# NUC1xx_registers register map
File version: 0.1
CPU: 
Registers are 32-bit, read-write, reset 0x0 unless marked. A register's access mark holds for its fields unless they carry their own. Offsets are from the block's base; [hi:lo] are bit positions; lines under a group give offsets from that group; {n}, {i} and the like mark numbered series.

## GPA — Registers group
Base 0x50004000
Same registers: GPB 0x50004040, GPC 0x50004080, GPD 0x500040C0, GPE 0x50004100
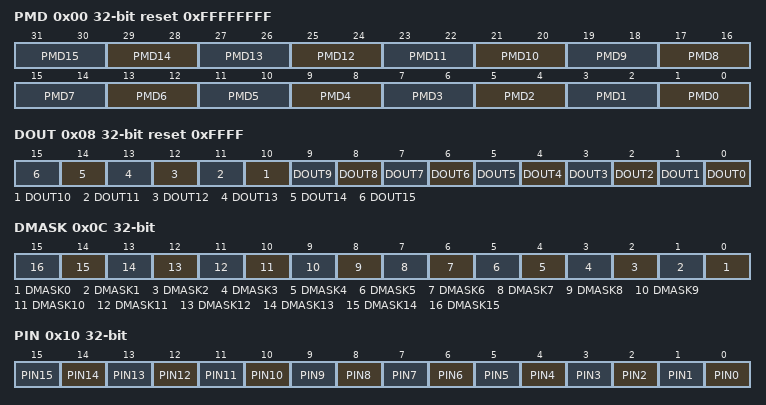
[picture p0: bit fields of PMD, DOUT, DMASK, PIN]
0x00 PMD reset 0xFFFFFFFF (reset mask 0x0) — GPIO Port Pin I/O Mode Control
  [2n+1:2n] PMD{n} (n=0..15) — GPIOX I/O Pin[n] Mode Control Determine each I/O type of GPIOx pins 00 = GPIO port [n] pin is in INPUT mode. 01 = GPIO port [n] pin is in OUTPUT mode. 10 = GPIO port [n] pin is in Open-Drain mode. 11 = GPIO port [n] pin is in Quasi-bidirectional mode.
0x04 OFFD — GPIO Port Pin OFF Digital Enable
  [31:16] OFFD — GPIOx Pin[n] OFF digital input path Enable Each of these bits is used to control if the input path of corresponding GPIO pin is disabled. If input is analog signal, users can OFF digital input path to avoid creepage 1 = Disable IO digital input path (digital input tied to low) 0 = Enable IO digital input path
0x08 DOUT reset 0xFFFF (reset mask 0xFFFF0000) — GPIO Port Data Output Value
  [n] DOUT{n} (n=0..15) — GPIOx Pin[n] Output Value Each of these bits control the status of a GPIO pin when the GPIO pin is configures as output, open-drain and quasi-mode. 1 = GPIO port [A/B/C/D/E] Pin[n] will drive High if the GPIO pin is configures as output, open-drain and quasi-mode. 0 = GPIO port [A/B/C/D/E] Pin[n] will drive Low if the GPIO pin is configures as output, open-drain and quasi-mode.
0x0C DMASK — GPIO Port Data Output Write Mask
  [n] DMASK{n} (n=0..15) — Port [A/B/C/D/E] Data Output Write Mask These bits are used to protect the corresponding register of GPIOx_DOUT bit[n]. When set the DMASK bit[n] to"1", the corresponding GPIOx_DOUTn bit is protected. The write signal is masked, write data to the protect bit is ignored 1 = The corresponding GPIOx_DOUT[n] bit is protected 0 = The corresponding GPIOx_DOUT[n] bit can be updated
0x10 PIN ro (reset mask 0xFFFF0000) — GPIO Port Pin Value
  [n] PIN{n} (n=0..15) — Port [A/B/C/D/E] Pin Values Each bit of the register reflects the actual status of the respective GPIO pin If bit is 1, it indicates the corresponding pin status is high, else the pin status is low
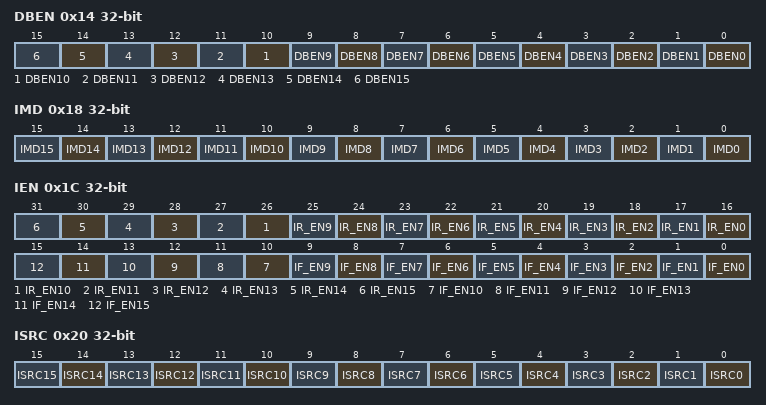
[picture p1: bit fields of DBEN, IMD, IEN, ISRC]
0x14 DBEN — GPIO Port De-bounce Enable
  [n] DBEN{n} (n=0..15) — Port [A/B/C/D/E] Input Signal De-bounce Enable DBEN[n]used to enable the de-bounce function for each corresponding bit. If the input signal pulse width can't be sampled by continuous two de-bounce sample cycle The input signal transition is seen as the signal bounce and will not trigger the interrupt. The de-bounce clock source is controlled by DBNCECON[4], one de-bounce sample cycle is controlled by DBNCECON[3:0] The DBEN[n] is used for "edge-trigger" interrupt only, and ignored for "level trigger" interrupt 1 = The bit[n] de-bounce function is enabled 0 = The bit[n] de-bounce function is disabled The de-bounce function is valid for edge triggered interrupt. If the interrupt mode is level triggered, the de-bounce enable bit is ignored.
0x18 IMD — GPIO Port Interrupt Mode Control
  [n] IMD{n} (n=0..15) — Port [A/B/C/D/E] Edge or Level Detection Interrupt Control IMD[n] is used to control the interrupt is by level trigger or by edge trigger. If the interrupt is by edge trigger, the trigger source can be controlled by de-bounce. If the interrupt is by level trigger, the input source is sampled by one HCLK clock and generates the interrup. 1 = Level trigger interrupt 0 = Edge trigger interrupt If set pin as the level trigger interrupt, then only one level can be set on the registers GPIOx_IEN. If set both the level to trigger interrupt, the setting is ignored and no interrupt will occur The de-bounce function is valid for edge triggered interrupt. If the interrupt mode is level triggered, the de-bounce enable bit is ignored.
0x1C IEN — GPIO Port Interrupt Enable
  [n+16] IR_EN{n} (n=0..15) — Port [A/B/C/D/E] Interrupt Enable by Input Rising Edge or Input Level High IR_EN[n] used to enable the interrupt for each of the corresponding input GPIO_PIN[n]. Set bit to 1 also enable the pin wakeup function When set the IR_EN[n] bit to 1: If the interrupt is level trigger, the input PIN[n] state at level "high" will generate the interrupt. If the interrupt is edge trigger, the input PIN[n] state change from "low-to-high" will generate the interrupt. 1 = Enable the PIN[n] level-high or low-to-high interrupt 0 = Disable the PIN[n] level-high or low-to-high interrupt.
  [n] IF_EN{n} (n=0..15) — Port [A/B/C/D/E] Interrupt Enable by Input Falling Edge or Input Level Low IF_EN[n] used to enable the interrupt for each of the corresponding input GPIO_PIN[n]. Set bit to 1 also enable the pin wakeup function When set the IF_EN[n] bit to 1: If the interrupt is level trigger, the input PIN[n] state at level "low" will generate the interrupt. If the interrupt is edge trigger, the input PIN[n] state change from "high-to-low" will generate the interrupt. 1 = Enable the PIN[n] state low-level or high-to-low change interrupt 0 = Disable the PIN[n] state low-level or high-to-low change interrupt
0x20 ISRC reset not defined — GPIO Port Interrupt Trigger Source Indicator
  [n] ISRC{n} write-1-clears (n=0..15) — Port [A/B/C/D/E] Interrupt Trigger Source Indicator Read : 1 = Indicates GPIOx[n] generate an interrupt 0 = No interrupt at GPIOx[n] Write : 1= Clear the correspond pending interrupt 0= No action
